VERSION "0.1"

BU_: IO

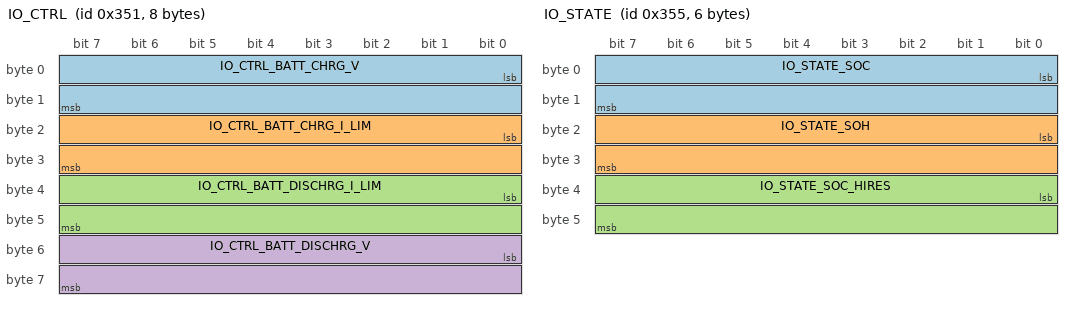
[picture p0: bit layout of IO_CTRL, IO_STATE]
BO_ 849 IO_CTRL: 8 IO
 SG_ IO_CTRL_BATT_CHRG_V : 0|16@1+ (0.1,0) [41|63] "V" IO
 SG_ IO_CTRL_BATT_CHRG_I_LIM : 16|16@1- (0.1,0) [0|1200] "A" IO
 SG_ IO_CTRL_BATT_DISCHRG_I_LIM : 32|16@1- (0.1,0) [0|1200] "A" IO
 SG_ IO_CTRL_BATT_DISCHRG_V : 48|16@1+ (0.1,0) [41|48] "V" IO

BO_ 853 IO_STATE: 6 IO
 SG_ IO_STATE_SOC : 0|16@1+ (1,0) [0|100] "%" IO
 SG_ IO_STATE_SOH : 16|16@1+ (1,0) [0|100] "%" IO
 SG_ IO_STATE_SOC_HIRES : 32|16@1+ (0.01,0) [0|100] "%" IO

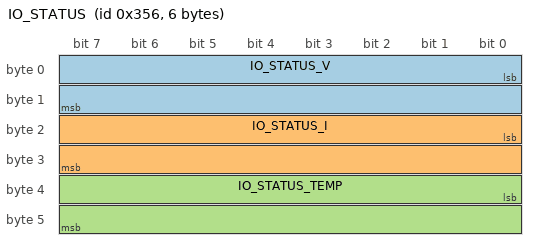
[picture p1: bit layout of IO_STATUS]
BO_ 854 IO_STATUS: 6 IO
 SG_ IO_STATUS_V : 0|16@1+ (0.01,0) [0|0] "V" IO
 SG_ IO_STATUS_I : 16|16@1+ (0.1,0) [0|0] "A" IO
 SG_ IO_STATUS_TEMP : 32|16@1+ (0.1,0) [0|0] "C" IO

BO_ 858 IO_ALARM: 8 IO
 SG_ IO_ALARM_GENERAL_ARRIVE : 0|1@1+ (1,0) [0|1] "" IO
 SG_ IO_ALARM_GENERAL_LEAVE : 1|1@1+ (1,0) [0|1] "" IO
 SG_ IO_ALARM_HIGH_V_ARRIVE : 2|1@1+ (1,0) [0|1] "" IO
 SG_ IO_ALARM_HIGH_V_LEAVE : 3|1@1+ (1,0) [0|1] "" IO
 SG_ IO_ALARM_LOW_V_ARRIVE : 4|1@1+ (1,0) [0|1] "" IO
 SG_ IO_ALARM_LOW_V_LEAVE : 5|1@1+ (1,0) [0|1] "" IO
 SG_ IO_ALARM_HIGH_TEMP_ARRIVE : 6|1@1+ (1,0) [0|1] "" IO
 SG_ IO_ALARM_HIGH_TEMP_LEAVE : 7|1@1+ (1,0) [0|1] "" IO
 SG_ IO_ALARM_LOW_TEMP_ARRIVE : 8|1@1+ (1,0) [0|1] "" IO
 SG_ IO_ALARM_LOW_TEMP_LEAVE : 9|1@1+ (1,0) [0|1] "" IO
 SG_ IO_ALARM_HIGH_TEMP_CHRG_ARRIVE : 10|1@1+ (1,0) [0|1] "" IO
 SG_ IO_ALARM_HIGH_TEMP_CHRG_LEAVE : 11|1@1+ (1,0) [0|1] "" IO
 SG_ IO_ALARM_LOW_TEMP_CHRG_ARRIVE : 12|1@1+ (1,0) [0|1] "" IO
 SG_ IO_ALARM_LOW_TEMP_CHRG_LEAVE : 13|1@1+ (1,0) [0|1] "" IO
 SG_ IO_ALARM_HIGH_I_ARRIVE : 14|1@1+ (1,0) [0|1] "" IO
 SG_ IO_ALARM_HIGH_I_LEAVE : 15|1@1+ (1,0) [0|1] "" IO
 SG_ IO_ALARM_HIGH_I_CHRG_ARRIVE : 16|1@1+ (1,0) [0|1] "" IO
 SG_ IO_ALARM_HIGH_I_CHRG_LEAVE : 17|1@1+ (1,0) [0|1] "" IO
 SG_ IO_ALARM_CONTACTOR_ARRIVE : 18|1@1+ (1,0) [0|1] "" IO
 SG_ IO_ALARM_CONTACTOR_LEAVE : 19|1@1+ (1,0) [0|1] "" IO
 SG_ IO_ALARM_SHORT_ARRIVE : 20|1@1+ (1,0) [0|1] "" IO
 SG_ IO_ALARM_SHORT_LEAVE : 21|1@1+ (1,0) [0|1] "" IO
 SG_ IO_ALARM_BMS_ARRIVE : 22|1@1+ (1,0) [0|1] "" IO
 SG_ IO_ALARM_BMS_LEAVE : 23|1@1+ (1,0) [0|1] "" IO
 SG_ IO_ALARM_CELL_IMBAL_ARRIVE : 24|1@1+ (1,0) [0|1] "" IO
 SG_ IO_ALARM_CELL_IMBAL_LEAVE : 25|1@1+ (1,0) [0|1] "" IO
 SG_ IO_ALARM_RESERVED_1_ARRIVE : 26|1@1+ (1,0) [0|1] "" IO
 SG_ IO_ALARM_RESERVED_1_LEAVE : 27|1@1+ (1,0) [0|1] "" IO
 SG_ IO_ALARM_RESERVED_2_ARRIVE : 28|1@1+ (1,0) [0|1] "" IO
 SG_ IO_ALARM_RESERVED_2_LEAVE : 29|1@1+ (1,0) [0|1] "" IO
 SG_ IO_ALARM_RESERVED_3_ARRIVE : 30|1@1+ (1,0) [0|1] "" IO
 SG_ IO_ALARM_RESERVED_3_LEAVE : 31|1@1+ (1,0) [0|1] "" IO
 SG_ IO_WARN_GENERAL_ARRIVE : 32|1@1+ (1,0) [0|1] "" IO
 SG_ IO_WARN_GENERAL_LEAVE : 33|1@1+ (1,0) [0|1] "" IO
 SG_ IO_WARN_HIGH_V_ARRIVE : 34|1@1+ (1,0) [0|1] "" IO
 SG_ IO_WARN_HIGH_V_LEAVE : 35|1@1+ (1,0) [0|1] "" IO
 SG_ IO_WARN_LOW_V_ARRIVE : 36|1@1+ (1,0) [0|1] "" IO
 SG_ IO_WARN_LOW_V_LEAVE : 37|1@1+ (1,0) [0|1] "" IO
 SG_ IO_WARN_HIGH_TEMP_ARRIVE : 38|1@1+ (1,0) [0|1] "" IO
 SG_ IO_WARN_HIGH_TEMP_LEAVE : 39|1@1+ (1,0) [0|1] "" IO
 SG_ IO_WARN_LOW_TEMP_ARRIVE : 40|1@1+ (1,0) [0|1] "" IO
 SG_ IO_WARN_LOW_TEMP_LEAVE : 41|1@1+ (1,0) [0|1] "" IO
 SG_ IO_WARN_HIGH_TEMP_CHRG_ARRIVE : 42|1@1+ (1,0) [0|1] "" IO
 SG_ IO_WARN_HIGH_TEMP_CHRG_LEAVE : 43|1@1+ (1,0) [0|1] "" IO
 SG_ IO_WARN_LOW_TEMP_CHRG_ARRIVE : 44|1@1+ (1,0) [0|1] "" IO
 SG_ IO_WARN_LOW_TEMP_CHRG_LEAVE : 45|1@1+ (1,0) [0|1] "" IO
 SG_ IO_WARN_HIGH_I_ARRIVE : 46|1@1+ (1,0) [0|1] "" IO
 SG_ IO_WARN_HIGH_I_LEAVE : 47|1@1+ (1,0) [0|1] "" IO
 SG_ IO_WARN_HIGH_I_CHRG_ARRIVE : 48|1@1+ (1,0) [0|1] "" IO
 SG_ IO_WARN_HIGH_I_CHRG_LEAVE : 49|1@1+ (1,0) [0|1] "" IO
 SG_ IO_WARN_CONTACTOR_ARRIVE : 50|1@1+ (1,0) [0|1] "" IO
 SG_ IO_WARN_CONTACTOR_LEAVE : 51|1@1+ (1,0) [0|1] "" IO
 SG_ IO_WARN_SHORT_ARRIVE : 52|1@1+ (1,0) [0|1] "" IO
 SG_ IO_WARN_SHORT_LEAVE : 53|1@1+ (1,0) [0|1] "" IO
 SG_ IO_WARN_BMS_ARRIVE : 54|1@1+ (1,0) [0|1] "" IO
 SG_ IO_WARN_BMS_LEAVE : 55|1@1+ (1,0) [0|1] "" IO
 SG_ IO_WARN_CELL_IMBAL_ARRIVE : 56|1@1+ (1,0) [0|1] "" IO
 SG_ IO_WARN_CELL_IMBAL_LEAVE : 57|1@1+ (1,0) [0|1] "" IO
 SG_ IO_WARN_RESERVED_1_ARRIVE : 58|1@1+ (1,0) [0|1] "" IO
 SG_ IO_WARN_RESERVED_1_LEAVE : 59|1@1+ (1,0) [0|1] "" IO
 SG_ IO_WARN_RESERVED_2_ARRIVE : 60|1@1+ (1,0) [0|1] "" IO
 SG_ IO_WARN_RESERVED_2_LEAVE : 61|1@1+ (1,0) [0|1] "" IO
 SG_ IO_WARN_RESERVED_3_ARRIVE : 62|1@1+ (1,0) [0|1] "" IO
 SG_ IO_WARN_RESERVED_3_LEAVE : 63|1@1+ (1,0) [0|1] "" IO
